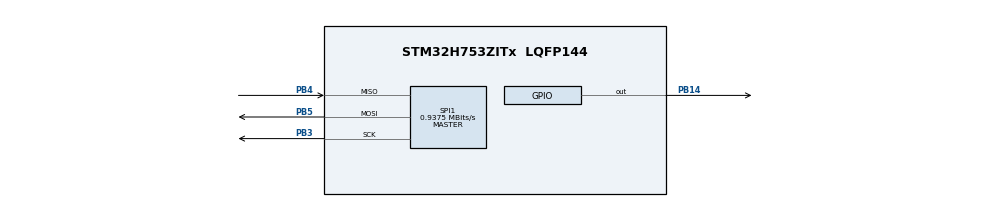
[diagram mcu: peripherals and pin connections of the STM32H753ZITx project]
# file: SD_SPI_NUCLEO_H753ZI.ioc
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CORTEX_M7.CPU_DCache=Disabled
CORTEX_M7.CPU_ICache=Disabled
CORTEX_M7.MPU_Control=__NULL
CORTEX_M7.default_mode_Activation=1
Mcu.Family=STM32H7
Mcu.Name=STM32H753ZITx
Mcu.Package=LQFP144
NUCLEO-H753ZI.VCP=true
NVIC.PriorityGroup=NVIC_PRIORITYGROUP_4
PB14.Signal=GPIO_Output
PB3\ (JTDO/TRACESWO).Mode=Full_Duplex_Master
PB3\ (JTDO/TRACESWO).Signal=SPI1_SCK
PB4\ (NJTRST).Mode=Full_Duplex_Master
PB4\ (NJTRST).Signal=SPI1_MISO
PB5.Mode=Full_Duplex_Master
PB5.Signal=SPI1_MOSI
PC14-OSC32_IN\ (OSC32_IN).Signal=RCC_OSC32_IN
PC15-OSC32_OUT\ (OSC32_OUT).Signal=RCC_OSC32_OUT
PD8.Signal=USART3_TX
PD9.Signal=USART3_RX
PH0-OSC_IN\ (PH0).Signal=RCC_OSC_IN
PH1-OSC_OUT\ (PH1).Signal=RCC_OSC_OUT
ProjectManager.HeapSize=0x200
ProjectManager.StackSize=0x400
ProjectManager.TargetToolchain=STM32CubeIDE
RCC.ADCFreq_Value=129000000
RCC.APB1Freq_Value=120000000
RCC.APB2Freq_Value=120000000
RCC.APB3Freq_Value=120000000
RCC.APB4Freq_Value=120000000
RCC.CortexFreq_Value=480000000
RCC.DIVM1=4
RCC.DIVN1=60
RCC.DIVQ1=4
RCC.HCLKFreq_Value=240000000
RCC.HSE_VALUE=8000000
RCC.PLLFRACN=0
RCC.PWR_Regulator_Voltage_Scale=PWR_REGULATOR_VOLTAGE_SCALE0
RCC.SYSCLKFreq_VALUE=480000000
RCC.USBFreq_Value=150000000
SPI1.BaudRatePrescaler=SPI_BAUDRATEPRESCALER_256
SPI1.CalculateBaudRate=0.9375 MBits/s
SPI1.Direction=SPI_DIRECTION_2LINES
SPI1.Mode=SPI_MODE_MASTER
SPI1.VirtualType=VM_MASTER
VP_MEMORYMAP_VS_MEMORYMAP.Mode=CurAppReg
VP_NUCLEO-H753ZI_VS_BSP_COMMON.Mode=COMMON
board=NUCLEO-H753ZI

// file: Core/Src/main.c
/* USER CODE BEGIN Header */
/**
  ******************************************************************************
  * @file           : main.c
  * @brief          : Main program body
  ******************************************************************************
  * @attention
  *
  * Copyright (c) 2026 STMicroelectronics.
  * All rights reserved.
  *
  * This software is licensed under terms that can be found in the LICENSE file
  * in the root directory of this software component.
  * If no LICENSE file comes with this software, it is provided AS-IS.
  *
  ******************************************************************************
  */
/* USER CODE END Header */
#include "main.h"

/* USER CODE BEGIN Includes */
#include "ff.h"
#include "diskio.h"
#include "sd_spi.h"
/* USER CODE END Includes */

COM_InitTypeDef BspCOMInit;

SPI_HandleTypeDef hspi1;

/* USER CODE BEGIN PV */
static FATFS g_fs;
static uint8_t g_sd_test_done = 0;
/* USER CODE END PV */

void SystemClock_Config(void);
static void MX_GPIO_Init(void);
static void MX_SPI1_Init(void);

int main(void)
{

  /* MCU Configuration--------------------------------------------------------*/

  /* Reset of all peripherals, Initializes the Flash interface and the Systick. */
  HAL_Init();

  /* Configure the system clock */
  SystemClock_Config();

  /* Initialize all configured peripherals */
  MX_GPIO_Init();
  MX_SPI1_Init();

  /* Initialize COM1 port (115200, 8 bits (7-bit data + 1 stop bit), no parity */
  BspCOMInit.BaudRate   = 115200;
  BspCOMInit.WordLength = COM_WORDLENGTH_8B;
  BspCOMInit.StopBits   = COM_STOPBITS_1;
  BspCOMInit.Parity     = COM_PARITY_NONE;
  BspCOMInit.HwFlowCtl  = COM_HWCONTROL_NONE;
  if (BSP_COM_Init(COM1, &BspCOMInit) != BSP_ERROR_NONE)
  {
    Error_Handler();
  }

  /* USER CODE BEGIN 3 */
  printf("\r\n--- STM32H7 SD Card Test ---\r\n");

  HAL_GPIO_WritePin(GPIOE, GPIO_PIN_14, GPIO_PIN_SET);
  HAL_Delay(20);

  /* Initialize SD card after UART is ready */
  if (SD_IO_Init()) {
    printf("SD Init: OK\r\n");
  } else {
    printf("SD Init: FAILED\r\n");
  }

  {
    FRESULT fr = f_mount(&g_fs, "", 1);
    if (fr == FR_OK) {
      printf("Mount: OK\r\n");
      g_sd_test_done = 1;
    } else if (fr == FR_NO_FILESYSTEM) {
      static uint8_t work[4096];
      printf("Mount: NO_FILESYSTEM, formatting...\r\n");
      if (f_mkfs("", FM_FAT32, 0, work, sizeof(work)) == FR_OK) {
        if (f_mount(&g_fs, "", 1) == FR_OK) {
          printf("Mount after mkfs: OK\r\n");
          g_sd_test_done = 1;
        } else {
          printf("Mount after mkfs: FAILED\r\n");
        }
      } else {
        printf("mkfs: FAILED\r\n");
      }
    } else {
      printf("Mount: FAILED (FR=%d)\r\n", (int)fr);
    }
  }

  /* USER CODE END 3 */

  /* Infinite loop */
  while (1)
  {

    /* USER CODE BEGIN 3 */
    if (g_sd_test_done) {
      g_sd_test_done = 0;

      {
        FIL fil;
        FRESULT fr;
        if (f_open(&fil, "test.txt", FA_CREATE_ALWAYS | FA_WRITE) == FR_OK) {
          UINT bw = 0;
          fr = f_write(&fil, "Hello from STM32H7!\r\n", 20, &bw);
          if (fr == FR_OK) {
            fr = f_sync(&fil);
          }
          f_close(&fil);
          if (fr == FR_OK) {
            printf("Wrote %u bytes to test.txt\r\n", bw);
          } else {
            printf("Write: FAILED (FR=%d, bw=%u)\r\n", (int)fr, bw);
          }
        } else {
          printf("Write: FAILED\r\n");
        }
      }

      {
        FIL fil;
        char buf[64] = {0};
        FRESULT fr;
        if (f_open(&fil, "test.txt", FA_READ) == FR_OK) {
          UINT br = 0;
          fr = f_read(&fil, buf, sizeof(buf) - 1, &br);
          f_close(&fil);
          if (fr == FR_OK) {
            printf("Read (%u): %s\r\n", br, buf);
          } else {
            printf("Read: FAILED (FR=%d)\r\n", (int)fr);
          }
        } else {
          printf("Read: FAILED\r\n");
        }
      }

      {
        DIR dir;
        FILINFO fno;
        printf("---\r\n");
        if (f_opendir(&dir, "/") == FR_OK) {
          while (f_readdir(&dir, &fno) == FR_OK) {
            if (fno.fname[0] == 0) break;
            if (!(fno.fattrib & AM_DIR)) {
              printf("%-12s %lu\r\n", fno.fname, (uint32_t)fno.fsize);
            }
          }
          f_closedir(&dir);
        }
        printf("---\r\n");
      }

      f_mount(0, "", 0);
      printf("Done.\r\n");
    }
  }
  /* USER CODE END 3 */
}

void SystemClock_Config(void)
{
  RCC_OscInitTypeDef RCC_OscInitStruct = {0};
  RCC_ClkInitTypeDef RCC_ClkInitStruct = {0};

  /** Supply configuration update enable
  */
  HAL_PWREx_ConfigSupply(PWR_LDO_SUPPLY);

  /** Configure the main internal regulator output voltage
  */
  __HAL_PWR_VOLTAGESCALING_CONFIG(PWR_REGULATOR_VOLTAGE_SCALE0);

  while(!__HAL_PWR_GET_FLAG(PWR_FLAG_VOSRDY)) {}

  /** Initializes the RCC Oscillators according to the specified parameters
  * in the RCC_OscInitTypeDef structure.
  */
  RCC_OscInitStruct.OscillatorType = RCC_OSCILLATORTYPE_HSI;
  RCC_OscInitStruct.HSIState = RCC_HSI_DIV1;
  RCC_OscInitStruct.HSICalibrationValue = RCC_HSICALIBRATION_DEFAULT;
  RCC_OscInitStruct.PLL.PLLState = RCC_PLL_ON;
  RCC_OscInitStruct.PLL.PLLSource = RCC_PLLSOURCE_HSI;
  RCC_OscInitStruct.PLL.PLLM = 4;
  RCC_OscInitStruct.PLL.PLLN = 60;
  RCC_OscInitStruct.PLL.PLLP = 2;
  RCC_OscInitStruct.PLL.PLLQ = 4;
  RCC_OscInitStruct.PLL.PLLR = 2;
  RCC_OscInitStruct.PLL.PLLRGE = RCC_PLL1VCIRANGE_3;
  RCC_OscInitStruct.PLL.PLLVCOSEL = RCC_PLL1VCOWIDE;
  RCC_OscInitStruct.PLL.PLLFRACN = 0;
  if (HAL_RCC_OscConfig(&RCC_OscInitStruct) != HAL_OK)
  {
    Error_Handler();
  }

  /** Initializes the CPU, AHB and APB buses clocks
  */
  RCC_ClkInitStruct.ClockType = RCC_CLOCKTYPE_HCLK|RCC_CLOCKTYPE_SYSCLK
                              |RCC_CLOCKTYPE_PCLK1|RCC_CLOCKTYPE_PCLK2
                              |RCC_CLOCKTYPE_D3PCLK1|RCC_CLOCKTYPE_D1PCLK1;
  RCC_ClkInitStruct.SYSCLKSource = RCC_SYSCLKSOURCE_PLLCLK;
  RCC_ClkInitStruct.SYSCLKDivider = RCC_SYSCLK_DIV1;
  RCC_ClkInitStruct.AHBCLKDivider = RCC_HCLK_DIV2;
  RCC_ClkInitStruct.APB3CLKDivider = RCC_APB3_DIV2;
  RCC_ClkInitStruct.APB1CLKDivider = RCC_APB1_DIV2;
  RCC_ClkInitStruct.APB2CLKDivider = RCC_APB2_DIV2;
  RCC_ClkInitStruct.APB4CLKDivider = RCC_APB4_DIV2;

  if (HAL_RCC_ClockConfig(&RCC_ClkInitStruct, FLASH_LATENCY_4) != HAL_OK)
  {
    Error_Handler();
  }
}

static void MX_SPI1_Init(void)
{

  /* SPI1 parameter configuration*/
  hspi1.Instance = SPI1;
  hspi1.Init.Mode = SPI_MODE_MASTER;
  hspi1.Init.Direction = SPI_DIRECTION_2LINES;
  hspi1.Init.DataSize = SPI_DATASIZE_8BIT;
  hspi1.Init.CLKPolarity = SPI_POLARITY_LOW;
  hspi1.Init.CLKPhase = SPI_PHASE_1EDGE;
  hspi1.Init.NSS = SPI_NSS_SOFT;
  hspi1.Init.BaudRatePrescaler = SPI_BAUDRATEPRESCALER_256;
  hspi1.Init.FirstBit = SPI_FIRSTBIT_MSB;
  hspi1.Init.TIMode = SPI_TIMODE_DISABLE;
  hspi1.Init.CRCCalculation = SPI_CRCCALCULATION_DISABLE;
  hspi1.Init.CRCPolynomial = 0x0;
  hspi1.Init.NSSPMode = SPI_NSS_PULSE_DISABLE;
  hspi1.Init.NSSPolarity = SPI_NSS_POLARITY_LOW;
  hspi1.Init.FifoThreshold = SPI_FIFO_THRESHOLD_01DATA;
  hspi1.Init.TxCRCInitializationPattern = SPI_CRC_INITIALIZATION_ALL_ZERO_PATTERN;
  hspi1.Init.RxCRCInitializationPattern = SPI_CRC_INITIALIZATION_ALL_ZERO_PATTERN;
  hspi1.Init.MasterSSIdleness = SPI_MASTER_SS_IDLENESS_00CYCLE;
  hspi1.Init.MasterInterDataIdleness = SPI_MASTER_INTERDATA_IDLENESS_00CYCLE;
  hspi1.Init.MasterReceiverAutoSusp = SPI_MASTER_RX_AUTOSUSP_DISABLE;
  hspi1.Init.MasterKeepIOState = SPI_MASTER_KEEP_IO_STATE_DISABLE;
  hspi1.Init.IOSwap = SPI_IO_SWAP_DISABLE;
  if (HAL_SPI_Init(&hspi1) != HAL_OK)
  {
    Error_Handler();
  }

}

static void MX_GPIO_Init(void)
{
  GPIO_InitTypeDef GPIO_InitStruct = {0};

  /* GPIO Ports Clock Enable */
  __HAL_RCC_GPIOC_CLK_ENABLE();
  __HAL_RCC_GPIOH_CLK_ENABLE();
  __HAL_RCC_GPIOB_CLK_ENABLE();
  __HAL_RCC_GPIOD_CLK_ENABLE();
  __HAL_RCC_GPIOE_CLK_ENABLE();

  /* Keep SD CS deselected: SD_CS(PE14/D4) */
  HAL_GPIO_WritePin(GPIOE, GPIO_PIN_14, GPIO_PIN_SET);

  /* Configure PE14 (SD_CS, Arduino D4) as output */
  GPIO_InitStruct.Pin = GPIO_PIN_14;
  GPIO_InitStruct.Mode = GPIO_MODE_OUTPUT_PP;
  GPIO_InitStruct.Pull = GPIO_NOPULL;
  GPIO_InitStruct.Speed = GPIO_SPEED_FREQ_LOW;
  HAL_GPIO_Init(GPIOE, &GPIO_InitStruct);

}

void Error_Handler(void)
{
  __disable_irq();
  while (1)
  {
  }
}
